# STM32WB05 register map
File version: 0.4
CPU: CM0+ r0p0, little endian, MPU, no FPU, 2 interrupt priority bits
Registers are 32-bit, read-write, reset 0x0 unless marked. A register's access mark holds for its fields unless they carry their own. Offsets are from the block's base; [hi:lo] are bit positions; {n}, {i} and the like mark numbered series.

## BLUE_REG
Base 0x60000000
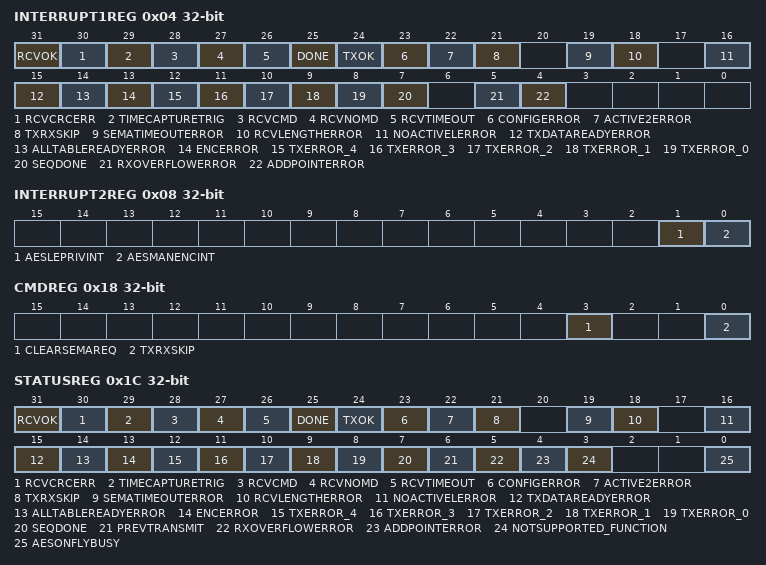
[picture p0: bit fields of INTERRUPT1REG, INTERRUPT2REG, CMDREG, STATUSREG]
0x04 INTERRUPT1REG
  [31] RCVOK — Receive data OK.
  [30] RCVCRCERR — Receive data fail
  [29] TIMECAPTURETRIG — A time has been captured in TIMERCAPTUREREG.
  [28] RCVCMD — Received command
  [27] RCVNOMD — Received low MD bit.
  [26] RCVTIMEOUT — Receive timeout (no preamble found).
  [25] DONE — Receive/Transmit done.
  [24] TXOK — Previous transmitted packet received OK by the peer device.
  [23] CONFIGERROR — Data pointer configuration error.
  [22] ACTIVE2ERROR — Active2 Radio state error.
  [21] TXRXSKIP — Transmission/Reception skip.
  [19] SEMATIMEOUTERROR — Semaphore timeout error
  [18] RCVLENGTHERROR — Receive length error.
  [16] NOACTIVELERROR — GlobalStatMach.
  [15] TXDATAREADYERROR — Transmit data pack not ready error
  [14] ALLTABLEREADYERROR — All RAM Table not ready on time.
  [13] ENCERROR — Encryption error on reception.
  [12] TXERROR_4 — Transmission error 4: a CTE issue occurred.
  [11] TXERROR_3 — Transmission error 3: error while waiting for the confirmation the Radio FSM is in TX state.
  [10] TXERROR_2 — Transmission error 2: channel index is greater than 39.
  [9] TXERROR_1 — Transmission error 1: a TX skip happened during an on-going transmission.
  [8] TXERROR_0 — Transmission error 0: transmit block missing data error.
  [7] SEQDONE — Sequencer end of task.
  [5] RXOVERFLOWERROR — Receive Overflow error.
  [4] ADDPOINTERROR — Address Pointer Error.
0x08 INTERRUPT2REG
  [1] AESLEPRIVINT — AES LE privacy engine.
  [0] AESMANENCINT — AES manual encryption.
0x0C TIMEOUTDESTREG
  [1:0] DESTINATION — Timeout timer Destination
0x10 TIMEOUTREG
  [31:0] TIMEOUT — Timer1 or Timer2 Timeout value (depending on Destination register)
0x14 TIMERCAPTUREREG ro
  [31:0] TIMERCAPTURE — Interpolated absolute time capture register
0x18 CMDREG wo
  [3] CLEARSEMAREQ — Semaphore Clear command.
  [0] TXRXSKIP — Transmission/Reception skip command.
0x1C STATUSREG ro
  [31] RCVOK — Receive data OK status
  [30] RCVCRCERR — Receive data fail (CRC error or invalid CI field) status.
  [29] TIMECAPTURETRIG — indicates a time has been captured in TIMERCAPTUREREG when set.
  [28] RCVCMD — Received command status (valid only on Data Physical Channel PDU reception).
  [27] RCVNOMD — Received MD bit status (valid only on Data Physical Channel PDU reception)
  [26] RCVTIMEOUT — Receive timeout status (no access address found)
  [25] DONE — Receive/Transmit done status.
  [24] TXOK — Previous transmitted packet received OK by the peer device status.
  [23] CONFIGERROR — Data pointer configuration error status
  [22] ACTIVE2ERROR — Indicates the Radio FSM was not in ACTIVE2 state when the Sequencer reaches the end of 1st INIT step.
  [21] TXRXSKIP — Transmission/Reception skip status.
  [19] SEMATIMEOUTERROR — Semaphore timeout error status
  [18] RCVLENGTHERROR — Receive length error status
  [16] NOACTIVELERROR — GlobalStatMach.
  [15] TXDATAREADYERROR — Transmit data pack not ready status.
  [14] ALLTABLEREADYERROR — All RAM Table not ready status
  [13] ENCERROR — Encryption error on receive status
  [12] TXERROR_4 — Transmission error 4 status
  [11] TXERROR_3 — Transmission error 3: error while waiting for the confirmation the Radio FSM is in TX state (timeout defined in GlobalStatMach.
  [10] TXERROR_2 — Transmission error 2 status.
  [9] TXERROR_1 — Transmission error 1 status
  [8] TXERROR_0 — Transmission error 0 status: Transmit block missing data error.
  [7] SEQDONE — Sequencer end of task status.
  [6] PREVTRANSMIT — Previous event was a Transmission (1) or Reception (0) status
  [5] RXOVERFLOWERROR — AHB arbiter is full and there is no more storage capability available in RX datapath
  [4] ADDPOINTERROR — Address Pointer Error status
  [3] NOTSUPPORTED_FUNCTION — indicates the SW requests an unsupported feature.
  [0] AESONFLYBUSY — AES on the fligh encryption busy status
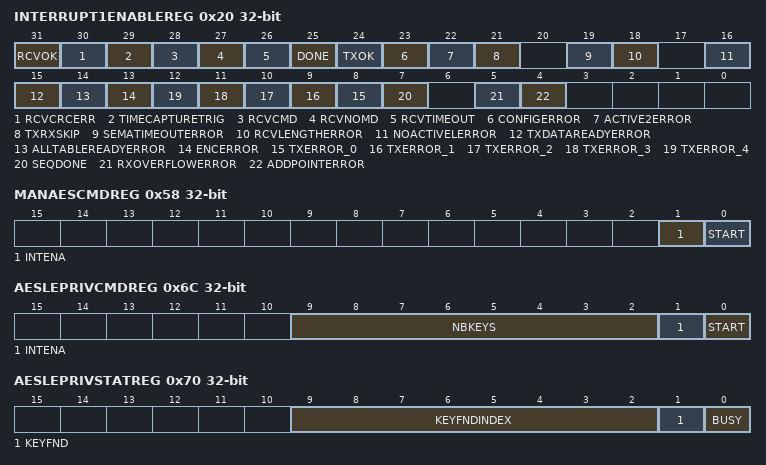
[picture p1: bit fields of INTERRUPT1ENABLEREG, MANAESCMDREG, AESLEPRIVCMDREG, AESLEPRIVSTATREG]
0x20 INTERRUPT1ENABLEREG ro
  [31] RCVOK — Receive data OK enable interruption
  [30] RCVCRCERR — Receive data fail enable interruption
  [29] TIMECAPTURETRIG — TimerCaptureReg time capture enable interruption
  [28] RCVCMD — Received command enable interruption
  [27] RCVNOMD — Received MD bit embedded in the PDU data packet header was zero enable interruption
  [26] RCVTIMEOUT — Receive timeout enable interruption (no preamble found)
  [25] DONE — Receive/Transmit done interruption
  [24] TXOK — Previous transmitted packet received OK enable interruption
  [23] CONFIGERROR — Data pointer configuration error enable interruption
  [22] ACTIVE2ERROR — Active2 Radio state error enable interruption
  [21] TXRXSKIP — Transmission/Reception skip enable interruption
  [19] SEMATIMEOUTERROR — Semaphore timeout error enable interruption
  [18] RCVLENGTHERROR — Receive length error enable interruption
  [16] NOACTIVELERROR — active bit error enable interruption
  [15] TXDATAREADYERROR — Transmit data pack not ready enable interruption
  [14] ALLTABLEREADYERROR — All RAM Table not ready enable interruption
  [13] ENCERROR — Encryption error on receive enable interruption
  [n+8] TXERROR_{n} (n=0..4) — Transmission error {n} enable interruption
  [7] SEQDONE — Sequencer end of task enable interruption
  [5] RXOVERFLOWERROR — Rx Overflow Error enable interruption
  [4] ADDPOINTERROR — Address Pointer Error enable interruption
0x24 INTERRUPT1LATENCYREG ro
  [7:0] INTERRUPT1LATENCY — relative time counter started on irq_BLE_int1 (BLE_TXRX) occurrence.
{0x28+4i} MANAESKEY{i}REG (i=0..3)
  [31:0] MANAESKEY_{32i+31}_{32i} — Manual mode AES key
{0x38+4i} MANAESCLEARTEXT{i}REG (i=0..3)
  [31:0] AES — Manual Aes Clear Text
{0x48+4i} MANAESCIPHERTEXT{i}REG ro (i=0..3)
  [31:0] AES — Manual AES Cipher Text
0x58 MANAESCMDREG
  [1] INTENA — AES Manual encryption interrupt enable on Interrupt2Reg
  [0] START wo — AES Manual encryption Start command.
0x5C MANAESSTATREG ro
  [0] BUSY — AES manual encryption busy status
0x60 AESLEPRIVPOINTERREG
  [23:0] POINTER — AES Le privacy pointer
0x64 AESLEPRIVHASHREG
  [23:0] HASH — AES Le privacy Reference Hash
0x68 AESLEPRIVPRANDREG
  [23:0] PRAND — AES Le privacy Prand
0x6C AESLEPRIVCMDREG
  [9:2] NBKEYS — AES Le privacy number of keys pointed by AesLePrivPointerReg (points to the resolution key list.
  [1] INTENA — AES Le privacy interrupt enable on Interrupt2Reg
  [0] START wo — AES Le privacy Start command.
0x70 AESLEPRIVSTATREG ro
  [9:2] KEYFNDINDEX — AES Le privacy index of the key found in the resolution key list.
  [1] KEYFND — AES Le privacy key finding status
  [0] BUSY — AES Le privacy busy status
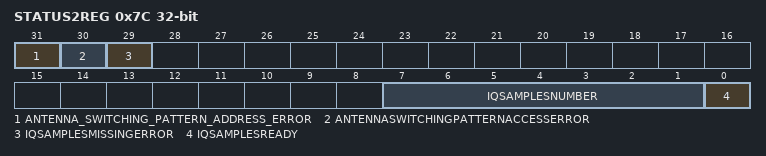
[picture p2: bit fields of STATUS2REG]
0x7C STATUS2REG ro
  [31] ANTENNA_SWITCHING_PATTERN_ADDRESS_ERROR — AHB access error flag.
  [30] ANTENNASWITCHINGPATTERNACCESSERROR — timing error flag related to Antenna Pattern not read on-time.
  [29] IQSAMPLESMISSINGERROR — IQ sample internal buffer overflow error flag.
  [7:1] IQSAMPLESNUMBER — indicate the number of IQ samples stored in the RAM buffer addressed by StatMach.
  [0] IQSAMPLESREADY — indicates if IQ samples have been received on the last reception.

## Notices in the file
Copyright (c) 2024 STMicroelectronics.
SPDX-License-Identifier: Apache-2.0
Licensed under the Apache License, Version 2.0 (the "License");
you may not use this file except in compliance with the License.
You may obtain a copy of the License at
http://www.apache.org/licenses/LICENSE-2.0
Unless required by applicable law or agreed to in writing, software
distributed under the License is distributed on an "AS IS" BASIS,
WITHOUT WARRANTIES OR CONDITIONS OF ANY KIND, either express or implied.
See the License for the specific language governing permissions and
limitations under the License.
